# nrf54lm20a_enga_application register map
Vendor: Nordic Semiconductor; Series: nrf54l; File version: 1
CPU: CM33 r0p4, little endian, MPU, FPU, 3 interrupt priority bits, 270 interrupts, 4 SAU regions
Registers are 32-bit, read-write, reset 0x0 unless marked. A register's access mark holds for its fields unless they carry their own. Offsets are from the block's base; [hi:lo] are bit positions; lines under a group give offsets from that group; {n}, {i} and the like mark numbered series; 'fields as' and 'values as' point back to an identical list.

## GLOBAL_SICR_S — Factory Information Configuration Registers
Base 0x00FFE000
0x00 CHIPCONF00 ro — Miscellaneous analog configuration. Will be set during production test.

## ICACHEDATA_S — CACHEDATA
Base 0x02F00000
{0x0+0x40*i} SET[{i}] (i=0..127) group — Unspecified
  {0x0+0x20*j} WAY[{j}] (j=0..1) group — Unspecified
    {0x0+8k} DU[{k}] (k=0..3) group — Unspecified
      {0x0+4l} DATA[{l}] (l=0..1) — Description collection: Cache data bits for DATA[q] in DU[p] (DataUnit) of SET[n], WAY[o].
        [31:0] Data ro

## ICACHEINFO_S — CACHEINFO
Base 0x02F10000
{0x0+8i} SET[{i}] (i=0..127) group — Unspecified
  {0x0+4j} WAY[{j}] (j=0..1) group — Unspecified
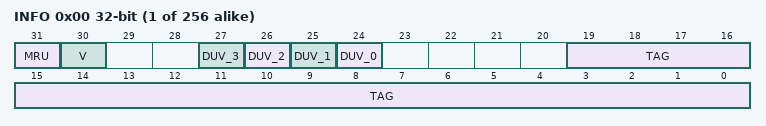
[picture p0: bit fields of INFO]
    0x00 INFO — Description cluster: Cache information for SET[n], WAY[o].
      [31] MRU ro — Most recently used way.
        0=Way0 was most recently used; 1=Way1 was most recently used
      [30] V ro — Line valid bit.
        0=Invalid cache line; 1=Valid cache line
      [n+24] DUV_{n} ro (n=0..3) — Data unit valid info.
        0=Invalid data unit; 1=Valid data unit
      [19:0] TAG ro — Cache tag.

## CPUC_S — CPU control
Base 0xE0080000
0x100 EVENTS_FPUIOC — An invalid operation exception has occurred in the FPU.
  [0] EVENTS_FPUIOC
    0=NotGenerated (Event not generated); 1=Generated (Event generated)
0x104 EVENTS_FPUDZC — A floating-point divide-by-zero exception has occurred in the FPU.
  [0] EVENTS_FPUDZC
    values as EVENTS_FPUIOC.EVENTS_FPUIOC
0x108 EVENTS_FPUOFC — A floating-point overflow exception has occurred in the FPU.
  [0] EVENTS_FPUOFC
    values as EVENTS_FPUIOC.EVENTS_FPUIOC
0x10C EVENTS_FPUUFC — A floating-point underflow exception has occurred in the FPU.
  [0] EVENTS_FPUUFC
    values as EVENTS_FPUIOC.EVENTS_FPUIOC
0x110 EVENTS_FPUIXC — A floating-point inexact exception has occurred in the FPU.
  [0] EVENTS_FPUIXC
    values as EVENTS_FPUIOC.EVENTS_FPUIOC
0x114 EVENTS_FPUIDC — A floating-point input denormal exception has occurred in the FPU.
  [0] EVENTS_FPUIDC
    values as EVENTS_FPUIOC.EVENTS_FPUIOC
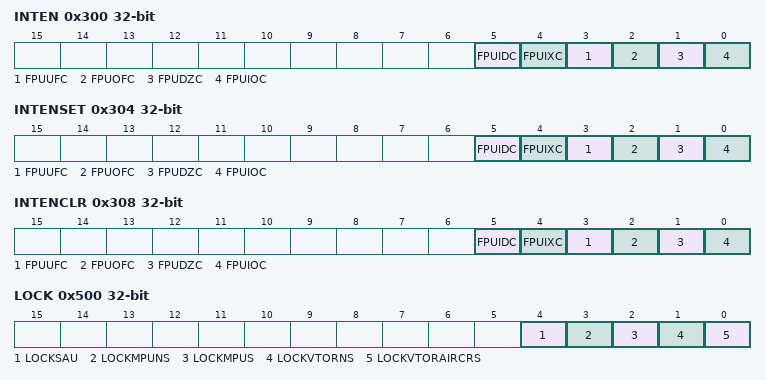
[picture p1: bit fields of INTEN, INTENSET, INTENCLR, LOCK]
0x300 INTEN — Enable or disable interrupt
  [all] fields
    0=Disabled; 1=Enabled
  [5] FPUIDC — Enable or disable interrupt for event FPUIDC
  [4] FPUIXC — Enable or disable interrupt for event FPUIXC
  [3] FPUUFC — Enable or disable interrupt for event FPUUFC
  [2] FPUOFC — Enable or disable interrupt for event FPUOFC
  [1] FPUDZC — Enable or disable interrupt for event FPUDZC
  [0] FPUIOC — Enable or disable interrupt for event FPUIOC
0x304 INTENSET — Enable interrupt
  [all] fields
    on read: 0=Disabled (Read: Disabled); 1=Enabled (Read: Enabled) | on write: 1=Set (Enable)
  [5] FPUIDC — Write '1' to enable interrupt for event FPUIDC
  [4] FPUIXC — Write '1' to enable interrupt for event FPUIXC
  [3] FPUUFC — Write '1' to enable interrupt for event FPUUFC
  [2] FPUOFC — Write '1' to enable interrupt for event FPUOFC
  [1] FPUDZC — Write '1' to enable interrupt for event FPUDZC
  [0] FPUIOC — Write '1' to enable interrupt for event FPUIOC
0x308 INTENCLR — Disable interrupt
  [all] fields
    on read: 0=Disabled (Read: Disabled); 1=Enabled (Read: Enabled) | on write: 1=Clear (Disable)
  [5] FPUIDC — Write '1' to disable interrupt for event FPUIDC
  [4] FPUIXC — Write '1' to disable interrupt for event FPUIXC
  [3] FPUUFC — Write '1' to disable interrupt for event FPUUFC
  [2] FPUOFC — Write '1' to disable interrupt for event FPUOFC
  [1] FPUDZC — Write '1' to disable interrupt for event FPUDZC
  [0] FPUIOC — Write '1' to disable interrupt for event FPUIOC
0x500 LOCK — Register to lock the certain parts of the CPU from being modified.
  [4] LOCKSAU — Locks the Security Attribution Unit (SAU)
    0=NotLocked (SAU registers can be changed.); 1=Locked (Prevents changes to SAU registers.)
  [3] LOCKMPUNS — Locks the Memory Protection Unit (MPU) for non secure mode.
    0=NotLocked (MPU registers can be changed.); 1=Locked (Prevents changes to MPU registers.)
  [2] LOCKMPUS — Locks the Memory Protection Unit (MPU) for secure mode.
    values as LOCKMPUNS
  [1] LOCKVTORNS — Locks the Vector table Offset Register (VTOR) for non-secure mode.
    0=NotLocked (VTOR can be changed.); 1=Locked (Prevents changes to VTOR.)
  [0] LOCKVTORAIRCRS — Locks both the Vector table Offset Register (VTOR) and Application Interrupt and Reset Control Register (AIRCR) for secure mode.
    0=NotLocked (Both VTOR and AIRCR can be changed.); 1=Locked (Prevents changes to both VTOR and AIRCR.)
0x504 CPUID ro — The identifier for the CPU in this subsystem.
  [31:0] CPUID — The CPU identifier.

## Notices in the file
Copyright (c) 2010 - 2025, Nordic Semiconductor ASA
All rights reserved.
Redistribution and use in source and binary forms, with or without modification,
are permitted provided that the following conditions are met:
1. Redistributions of source code must retain the above copyright notice, this
list of conditions and the following disclaimer.
2. Redistributions in binary form, except as embedded into a Nordic
Semiconductor ASA integrated circuit in a product or a software update for
such product, must reproduce the above copyright notice, this list of
conditions and the following disclaimer in the documentation and/or other
materials provided with the distribution.
3. Neither the name of Nordic Semiconductor ASA nor the names of its
contributors may be used to endorse or promote products derived from this
software without specific prior written permission.
4. This software, with or without modification, must only be used with a
Nordic Semiconductor ASA integrated circuit.
5. Any software provided in binary form under this license must not be reverse
engineered, decompiled, modified and/or disassembled.
THIS SOFTWARE IS PROVIDED BY NORDIC SEMICONDUCTOR ASA "AS IS" AND ANY EXPRESS
OR IMPLIED WARRANTIES, INCLUDING, BUT NOT LIMITED TO, THE IMPLIED WARRANTIES
OF MERCHANTABILITY, NONINFRINGEMENT, AND FITNESS FOR A PARTICULAR PURPOSE ARE
DISCLAIMED. IN NO EVENT SHALL NORDIC SEMICONDUCTOR ASA OR CONTRIBUTORS BE
LIABLE FOR ANY DIRECT, INDIRECT, INCIDENTAL, SPECIAL, EXEMPLARY, OR
CONSEQUENTIAL DAMAGES (INCLUDING, BUT NOT LIMITED TO, PROCUREMENT OF SUBSTITUTE
GOODS OR SERVICES; LOSS OF USE, DATA, OR PROFITS; OR BUSINESS INTERRUPTION)
HOWEVER CAUSED AND ON ANY THEORY OF LIABILITY, WHETHER IN CONTRACT, STRICT
LIABILITY, OR TORT (INCLUDING NEGLIGENCE OR OTHERWISE) ARISING IN ANY WAY OUT
OF THE USE OF THIS SOFTWARE, EVEN IF ADVISED OF THE POSSIBILITY OF SUCH DAMAGE.
